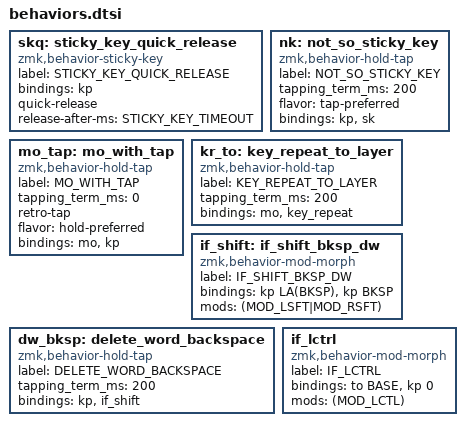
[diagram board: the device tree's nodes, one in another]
    skq: sticky_key_quick_release {
      compatible = "zmk,behavior-sticky-key";
      label = "STICKY_KEY_QUICK_RELEASE";
      #binding-cells = <1>;
      bindings = <&kp>;
      quick-release;
      release-after-ms = <STICKY_KEY_TIMEOUT>;
    };

    // Sticky key on tap, normal key on hold
    // Useful for modifier-clicking without the modifier remaining active
    nk: not_so_sticky_key {
      compatible = "zmk,behavior-hold-tap";
      label = "NOT_SO_STICKY_KEY";
      #binding-cells = <2>;
      tapping_term_ms = <200>;
      flavor = "tap-preferred";
      bindings = <&kp>, <&sk>;
    };

    // A hold-tap that activates without delay (like `&mo`)
    mo_tap: mo_with_tap {
      compatible = "zmk,behavior-hold-tap";
      label = "MO_WITH_TAP";
      #binding-cells = <2>;
      tapping_term_ms = <0>;
      retro-tap;
      flavor = "hold-preferred";
      bindings = <&mo>, <&kp>;
    };

    kr_to: key_repeat_to_layer {
        compatible = "zmk,behavior-hold-tap";
        label = "KEY_REPEAT_TO_LAYER";
        #binding-cells = <2>;
        tapping_term_ms = <200>;
        bindings = <&mo>, <&key_repeat>;
    };

    if_shift: if_shift_bksp_dw {
        compatible = "zmk,behavior-mod-morph";
        label = "IF_SHIFT_BKSP_DW";
        #binding-cells = <0>;
        bindings = <&kp LA(BKSP)>, <&kp BKSP>;
        mods = <(MOD_LSFT|MOD_RSFT)>;
    };

    dw_bksp: delete_word_backspace {
        compatible = "zmk,behavior-hold-tap";
        label = "DELETE_WORD_BACKSPACE";
        #binding-cells = <2>;
        tapping_term_ms = <200>;
        bindings = <&kp>, <&if_shift>;
    };

    if_lctrl: if_lctrl {
        compatible = "zmk,behavior-mod-morph";
        label = "IF_LCTRL";
        #binding-cells = <0>;
        bindings = <&to BASE>, <&kp 0>;
        mods = <(MOD_LCTL)>;
    };
